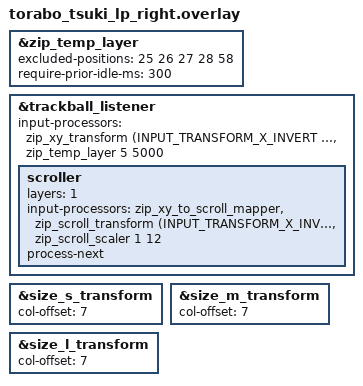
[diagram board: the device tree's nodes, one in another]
#include "torabo_tsuki_lp.dtsi"
#include <input/processors.dtsi>
#include <dt-bindings/zmk/input_transform.h>

// Auto Mouse Layer用のzip_temp_layer設定
&zip_temp_layer {
     excluded-positions = <
         // 左手モディファイアキー
         25 // A (tap:A / hold:Ctrl)
         26 // S (tap:S / hold:Cmd)
         27 // D (tap:D / hold:Alt)
         28 // F (tap:F / hold:Shift)

         // 右手モディファイア・マウスクリックキー
         // 33 // J (base:J/Shift / mouse:LCLK) ※AML中クリック可能  
         // 34 // K (base:K/Alt / mouse:RCLK) ※AML中クリック可能
         // 49 // dot (mouse:RCLK)
         58 // left thumbs right
         // 61 // right thumb key
     >;
    require-prior-idle-ms = <300>; // キー入力中の誤爆防止
};

&trackball_listener {
    input-processors =
      <&zip_xy_transform (INPUT_TRANSFORM_X_INVERT | INPUT_TRANSFORM_Y_INVERT)>,
      <&zip_temp_layer 5 5000>
    ;

	scroller {
	    layers = <1>;
        input-processors =
            <&zip_xy_to_scroll_mapper>,
            <&zip_scroll_transform (INPUT_TRANSFORM_X_INVERT | INPUT_TRANSFORM_Y_INVERT)>,
            <&zip_scroll_scaler 1 12>;
            /* <&zip_scroll_x_scaler 0 1>, */
            /* <&zip_scroll_scaler 1 12>; */
            /* <&zip_inertia>; */
        process-next;
    };
};

&size_s_transform {
    col-offset = <7>;
};

&size_m_transform {
    col-offset = <7>;
};

&size_l_transform {
    col-offset = <7>;
};
